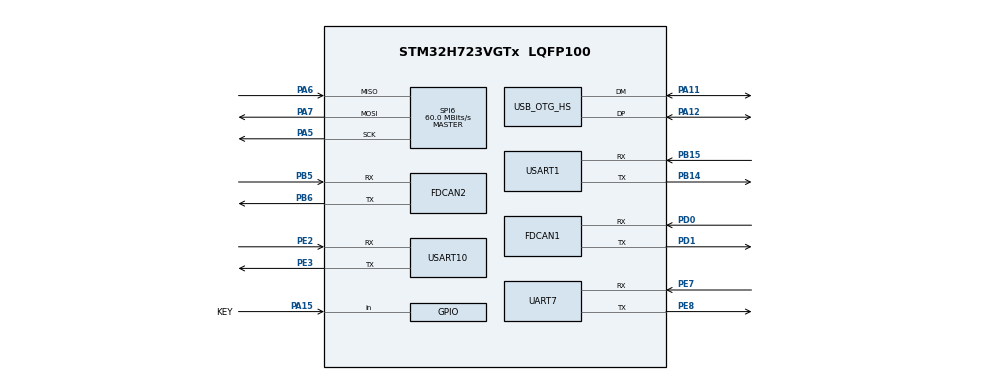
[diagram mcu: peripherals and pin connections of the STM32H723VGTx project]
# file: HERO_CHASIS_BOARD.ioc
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CORTEX_M7.default_mode_Activation=1
Dma.Request0=USART10_RX
Dma.Request1=USART10_TX
Dma.Request2=USART1_RX
Dma.Request3=UART7_RX
Dma.Request4=UART7_TX
Dma.UART7_RX.3.Direction=DMA_PERIPH_TO_MEMORY
Dma.UART7_RX.3.EventEnable=DISABLE
Dma.UART7_RX.3.FIFOMode=DMA_FIFOMODE_DISABLE
Dma.UART7_RX.3.Instance=DMA1_Stream3
Dma.UART7_RX.3.MemDataAlignment=DMA_MDATAALIGN_BYTE
Dma.UART7_RX.3.MemInc=DMA_MINC_ENABLE
Dma.UART7_RX.3.Mode=DMA_CIRCULAR
Dma.UART7_RX.3.PeriphDataAlignment=DMA_PDATAALIGN_BYTE
Dma.UART7_RX.3.PeriphInc=DMA_PINC_DISABLE
Dma.UART7_RX.3.Polarity=HAL_DMAMUX_REQ_GEN_RISING
Dma.UART7_RX.3.Priority=DMA_PRIORITY_HIGH
Dma.UART7_RX.3.RequestNumber=1
Dma.UART7_RX.3.SignalID=NONE
Dma.UART7_RX.3.SyncEnable=DISABLE
Dma.UART7_RX.3.SyncPolarity=HAL_DMAMUX_SYNC_NO_EVENT
Dma.UART7_RX.3.SyncRequestNumber=1
Dma.UART7_RX.3.SyncSignalID=NONE
Dma.UART7_TX.4.Direction=DMA_MEMORY_TO_PERIPH
Dma.UART7_TX.4.EventEnable=DISABLE
Dma.UART7_TX.4.FIFOMode=DMA_FIFOMODE_DISABLE
Dma.UART7_TX.4.Instance=DMA1_Stream4
Dma.UART7_TX.4.MemDataAlignment=DMA_MDATAALIGN_BYTE
Dma.UART7_TX.4.MemInc=DMA_MINC_ENABLE
Dma.UART7_TX.4.Mode=DMA_NORMAL
Dma.UART7_TX.4.PeriphDataAlignment=DMA_PDATAALIGN_BYTE
Dma.UART7_TX.4.PeriphInc=DMA_PINC_DISABLE
Dma.UART7_TX.4.Polarity=HAL_DMAMUX_REQ_GEN_RISING
Dma.UART7_TX.4.Priority=DMA_PRIORITY_MEDIUM
Dma.UART7_TX.4.RequestNumber=1
Dma.UART7_TX.4.SignalID=NONE
Dma.UART7_TX.4.SyncEnable=DISABLE
Dma.UART7_TX.4.SyncPolarity=HAL_DMAMUX_SYNC_NO_EVENT
Dma.UART7_TX.4.SyncRequestNumber=1
Dma.UART7_TX.4.SyncSignalID=NONE
Dma.USART10_RX.0.Direction=DMA_PERIPH_TO_MEMORY
Dma.USART10_RX.0.EventEnable=DISABLE
Dma.USART10_RX.0.FIFOMode=DMA_FIFOMODE_DISABLE
Dma.USART10_RX.0.Instance=DMA1_Stream0
Dma.USART10_RX.0.MemDataAlignment=DMA_MDATAALIGN_BYTE
Dma.USART10_RX.0.MemInc=DMA_MINC_ENABLE
Dma.USART10_RX.0.Mode=DMA_CIRCULAR
Dma.USART10_RX.0.PeriphDataAlignment=DMA_PDATAALIGN_BYTE
Dma.USART10_RX.0.PeriphInc=DMA_PINC_DISABLE
Dma.USART10_RX.0.Polarity=HAL_DMAMUX_REQ_GEN_RISING
Dma.USART10_RX.0.Priority=DMA_PRIORITY_LOW
Dma.USART10_RX.0.RequestNumber=1
Dma.USART10_RX.0.SignalID=NONE
Dma.USART10_RX.0.SyncEnable=DISABLE
Dma.USART10_RX.0.SyncPolarity=HAL_DMAMUX_SYNC_NO_EVENT
Dma.USART10_RX.0.SyncRequestNumber=1
Dma.USART10_RX.0.SyncSignalID=NONE
Dma.USART10_TX.1.Direction=DMA_MEMORY_TO_PERIPH
Dma.USART10_TX.1.EventEnable=DISABLE
Dma.USART10_TX.1.FIFOMode=DMA_FIFOMODE_DISABLE
Dma.USART10_TX.1.Instance=DMA1_Stream1
Dma.USART10_TX.1.MemDataAlignment=DMA_MDATAALIGN_BYTE
Dma.USART10_TX.1.MemInc=DMA_MINC_ENABLE
Dma.USART10_TX.1.Mode=DMA_NORMAL
Dma.USART10_TX.1.PeriphDataAlignment=DMA_PDATAALIGN_BYTE
Dma.USART10_TX.1.PeriphInc=DMA_PINC_DISABLE
Dma.USART10_TX.1.Polarity=HAL_DMAMUX_REQ_GEN_RISING
Dma.USART10_TX.1.Priority=DMA_PRIORITY_LOW
Dma.USART10_TX.1.RequestNumber=1
Dma.USART10_TX.1.SignalID=NONE
Dma.USART10_TX.1.SyncEnable=DISABLE
Dma.USART10_TX.1.SyncPolarity=HAL_DMAMUX_SYNC_NO_EVENT
Dma.USART10_TX.1.SyncRequestNumber=1
Dma.USART10_TX.1.SyncSignalID=NONE
Dma.USART1_RX.2.Direction=DMA_PERIPH_TO_MEMORY
Dma.USART1_RX.2.EventEnable=DISABLE
Dma.USART1_RX.2.FIFOMode=DMA_FIFOMODE_DISABLE
Dma.USART1_RX.2.Instance=DMA1_Stream2
Dma.USART1_RX.2.MemDataAlignment=DMA_MDATAALIGN_BYTE
Dma.USART1_RX.2.MemInc=DMA_MINC_ENABLE
Dma.USART1_RX.2.Mode=DMA_CIRCULAR
Dma.USART1_RX.2.PeriphDataAlignment=DMA_PDATAALIGN_BYTE
Dma.USART1_RX.2.PeriphInc=DMA_PINC_DISABLE
Dma.USART1_RX.2.Polarity=HAL_DMAMUX_REQ_GEN_RISING
Dma.USART1_RX.2.Priority=DMA_PRIORITY_HIGH
Dma.USART1_RX.2.RequestNumber=1
Dma.USART1_RX.2.SignalID=NONE
Dma.USART1_RX.2.SyncEnable=DISABLE
Dma.USART1_RX.2.SyncPolarity=HAL_DMAMUX_SYNC_NO_EVENT
Dma.USART1_RX.2.SyncRequestNumber=1
Dma.USART1_RX.2.SyncSignalID=NONE
FDCAN1.CalculateBaudRateNominal=1000000
FDCAN1.CalculateTimeBitNominal=1000
FDCAN1.CalculateTimeQuantumNominal=25.0
FDCAN1.DataPrescaler=3
FDCAN1.DataSyncJumpWidth=10
FDCAN1.DataTimeSeg1=29
FDCAN1.DataTimeSeg2=10
FDCAN1.NominalPrescaler=3
FDCAN1.NominalSyncJumpWidth=10
FDCAN1.NominalTimeSeg1=29
FDCAN1.NominalTimeSeg2=10
FDCAN1.ProtocolException=ENABLE
FDCAN1.RxFifo0ElmtsNbr=3
FDCAN1.StdFiltersNbr=1
FDCAN1.TxFifoQueueElmtsNbr=3
FDCAN2.CalculateBaudRateNominal=1000000
FDCAN2.CalculateTimeBitNominal=1000
FDCAN2.CalculateTimeQuantumNominal=25.0
FDCAN2.DataPrescaler=3
FDCAN2.DataSyncJumpWidth=10
FDCAN2.DataTimeSeg1=29
FDCAN2.DataTimeSeg2=10
FDCAN2.NominalPrescaler=3
FDCAN2.NominalSyncJumpWidth=10
FDCAN2.NominalTimeSeg1=29
FDCAN2.NominalTimeSeg2=10
FDCAN2.ProtocolException=ENABLE
FDCAN2.RxFifo0ElmtsNbr=3
FDCAN2.StdFiltersNbr=1
FDCAN2.TxFifoQueueElmtsNbr=3
FREERTOS.Tasks01=defaultTask,24,128,StartDefaultTask,Default,NULL,Dynamic,NULL,NULL
Mcu.Family=STM32H7
Mcu.Name=STM32H723VGTx
Mcu.Package=LQFP100
NVIC.DMA1_Stream0_IRQn=true\:5\:0\:false\:false\:true\:true\:false\:true\:true
NVIC.DMA1_Stream1_IRQn=true\:5\:0\:false\:false\:true\:true\:false\:true\:true
NVIC.DMA1_Stream2_IRQn=true\:5\:0\:false\:false\:true\:true\:false\:true\:true
NVIC.DMA1_Stream3_IRQn=true\:5\:0\:false\:false\:true\:true\:false\:true\:true
NVIC.DMA1_Stream4_IRQn=true\:5\:0\:false\:false\:true\:true\:false\:true\:true
NVIC.OTG_HS_IRQn=true\:5\:0\:false\:false\:true\:true\:false\:true\:true
NVIC.PriorityGroup=NVIC_PRIORITYGROUP_4
NVIC.TIM8_UP_TIM13_IRQn=true\:15\:0\:false\:false\:true\:false\:false\:true\:true
NVIC.TimeBase=TIM8_UP_TIM13_IRQn
NVIC.TimeBaseIP=TIM8
NVIC.UART7_IRQn=true\:5\:0\:false\:false\:true\:true\:true\:true\:true
NVIC.USART10_IRQn=true\:5\:0\:false\:false\:true\:true\:true\:true\:true
NVIC.USART1_IRQn=true\:5\:0\:false\:false\:true\:true\:true\:true\:true
PA11.Mode=Device_Only_FS
PA11.Signal=USB_OTG_HS_DM
PA12.Mode=Device_Only_FS
PA12.Signal=USB_OTG_HS_DP
PA13(JTMS/SWDIO).Mode=Serial_Wire
PA13(JTMS/SWDIO).Signal=DEBUG_JTMS-SWDIO
PA14(JTCK/SWCLK).Mode=Serial_Wire
PA14(JTCK/SWCLK).Signal=DEBUG_JTCK-SWCLK
PA15(JTDI).GPIO_Label=KEY
PA15(JTDI).GPIO_PuPd=GPIO_PULLUP
PA15(JTDI).Signal=GPIO_Input
PA5.Mode=Full_Duplex_Master
PA5.Signal=SPI6_SCK
PA6.Mode=Full_Duplex_Master
PA6.Signal=SPI6_MISO
PA7.Mode=Full_Duplex_Master
PA7.Signal=SPI6_MOSI
PB14.Mode=Asynchronous
PB14.Signal=USART1_TX
PB15.Mode=Asynchronous
PB15.Signal=USART1_RX
PB5.Mode=FDCAN_Activate
PB5.Signal=FDCAN2_RX
PB6.Mode=FDCAN_Activate
PB6.Signal=FDCAN2_TX
PD0.Mode=FDCAN_Activate
PD0.Signal=FDCAN1_RX
PD1.Mode=FDCAN_Activate
PD1.Signal=FDCAN1_TX
PE2.Mode=Asynchronous
PE2.Signal=USART10_RX
PE3.Mode=Asynchronous
PE3.Signal=USART10_TX
PE7.Mode=Asynchronous
PE7.Signal=UART7_RX
PE8.Mode=Asynchronous
PE8.Signal=UART7_TX
PH0-OSC_IN.Mode=HSE-External-Oscillator
PH0-OSC_IN.Signal=RCC_OSC_IN
PH1-OSC_OUT.Mode=HSE-External-Oscillator
PH1-OSC_OUT.Signal=RCC_OSC_OUT
ProjectManager.HeapSize=0x200
ProjectManager.StackSize=0x400
ProjectManager.TargetToolchain=MDK-ARM V5.32
RCC.ADCFreq_Value=120000000
RCC.APB1Freq_Value=120000000
RCC.APB2Freq_Value=120000000
RCC.APB3Freq_Value=120000000
RCC.APB4Freq_Value=120000000
RCC.CortexFreq_Value=480000000
RCC.D1PPRE=RCC_APB3_DIV2
RCC.D2PPRE1=RCC_APB1_DIV2
RCC.D2PPRE2=RCC_APB2_DIV2
RCC.D3PPRE=RCC_APB4_DIV2
RCC.DIVM1=2
RCC.DIVM2=2
RCC.DIVN1=40
RCC.DIVN2=20
RCC.DIVP1=1
RCC.FDCANCLockSelection=RCC_FDCANCLKSOURCE_PLL2
RCC.HCLKFreq_Value=240000000
RCC.HPRE=RCC_HCLK_DIV2
RCC.HSE_VALUE=24000000
RCC.PLL2FRACN=0
RCC.PLLFRACN=0
RCC.PLLSourceVirtual=RCC_PLLSOURCE_HSE
RCC.SYSCLKFreq_VALUE=480000000
RCC.SYSCLKSource=RCC_SYSCLKSOURCE_PLLCLK
RCC.USBCLockSelection=RCC_USBCLKSOURCE_HSI48
RCC.USBFreq_Value=48000000
SPI6.CalculateBaudRate=60.0 MBits/s
SPI6.Direction=SPI_DIRECTION_2LINES
SPI6.Mode=SPI_MODE_MASTER
SPI6.VirtualType=VM_MASTER
USART1.VirtualMode-Asynchronous=VM_ASYNC
USART10.VirtualMode=VM_ASYNC
USB_DEVICE.CLASS_NAME_HS=CDC
USB_DEVICE.VirtualMode=Cdc
USB_DEVICE.VirtualModeHS=Cdc_HS
USB_OTG_HS.VirtualMode-Device_Only_FS=Device_Only_FS
VP_FREERTOS_VS_CMSIS_V2.Mode=CMSIS_V2
VP_MEMORYMAP_VS_MEMORYMAP.Mode=CurAppReg
VP_SYS_VS_tim8.Mode=TIM8
VP_USB_DEVICE_VS_USB_DEVICE_CDC_HS.Mode=CDC_HS
board=custom

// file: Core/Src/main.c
/* USER CODE BEGIN Header */
/**
  ******************************************************************************
  * @file           : main.c
  * @brief          : Main program body
  ******************************************************************************
  * @attention
  *
  * Copyright (c) 2025 STMicroelectronics.
  * All rights reserved.
  *
  * This software is licensed under terms that can be found in the LICENSE file
  * in the root directory of this software component.
  * If no LICENSE file comes with this software, it is provided AS-IS.
  *
  ******************************************************************************
  */
/* USER CODE END Header */
#include "main.h"
#include "cmsis_os.h"
#include "dma.h"
#include "fdcan.h"
#include "spi.h"
#include "usart.h"
#include "usb_device.h"
#include "gpio.h"

/* USER CODE BEGIN Includes */
#include "usbd_cdc_if.h"

/* USER CODE END Includes */

void SystemClock_Config(void);
void PeriphCommonClock_Config(void);
static void MPU_Config(void);
void MX_FREERTOS_Init(void);

int main(void)
{

  /* MPU Configuration--------------------------------------------------------*/
  MPU_Config();

  /* MCU Configuration--------------------------------------------------------*/

  /* Reset of all peripherals, Initializes the Flash interface and the Systick. */
  HAL_Init();

  /* Configure the system clock */
  SystemClock_Config();

  /* Configure the peripherals common clocks */
  PeriphCommonClock_Config();

  /* Initialize all configured peripherals */
  MX_GPIO_Init();
  MX_DMA_Init();
  MX_FDCAN1_Init();
  MX_FDCAN2_Init();
  MX_SPI6_Init();
  MX_USART10_UART_Init();
  MX_USART1_UART_Init();
  MX_UART7_Init();

  /* Init scheduler */
  osKernelInitialize();  /* Call init function for freertos objects (in cmsis_os2.c) */
  MX_FREERTOS_Init();

  /* Start scheduler */
  osKernelStart();

  /* We should never get here as control is now taken by the scheduler */

  /* Infinite loop */
  /* USER CODE BEGIN WHILE */
  while (1)
  {
    usb_printf("Hello World!\r\n");

    /* USER CODE END WHILE */

  }
}

void SystemClock_Config(void)
{
  RCC_OscInitTypeDef RCC_OscInitStruct = {0};
  RCC_ClkInitTypeDef RCC_ClkInitStruct = {0};

  /** Supply configuration update enable
  */
  HAL_PWREx_ConfigSupply(PWR_LDO_SUPPLY);

  /** Configure the main internal regulator output voltage
  */
  __HAL_PWR_VOLTAGESCALING_CONFIG(PWR_REGULATOR_VOLTAGE_SCALE0);

  while(!__HAL_PWR_GET_FLAG(PWR_FLAG_VOSRDY)) {}

  /** Initializes the RCC Oscillators according to the specified parameters
  * in the RCC_OscInitTypeDef structure.
  */
  RCC_OscInitStruct.OscillatorType = RCC_OSCILLATORTYPE_HSI48|RCC_OSCILLATORTYPE_HSE;
  RCC_OscInitStruct.HSEState = RCC_HSE_ON;
  RCC_OscInitStruct.HSI48State = RCC_HSI48_ON;
  RCC_OscInitStruct.PLL.PLLState = RCC_PLL_ON;
  RCC_OscInitStruct.PLL.PLLSource = RCC_PLLSOURCE_HSE;
  RCC_OscInitStruct.PLL.PLLM = 2;
  RCC_OscInitStruct.PLL.PLLN = 40;
  RCC_OscInitStruct.PLL.PLLP = 1;
  RCC_OscInitStruct.PLL.PLLQ = 2;
  RCC_OscInitStruct.PLL.PLLR = 2;
  RCC_OscInitStruct.PLL.PLLRGE = RCC_PLL1VCIRANGE_3;
  RCC_OscInitStruct.PLL.PLLVCOSEL = RCC_PLL1VCOWIDE;
  RCC_OscInitStruct.PLL.PLLFRACN = 0;
  if (HAL_RCC_OscConfig(&RCC_OscInitStruct) != HAL_OK)
  {
    Error_Handler();
  }

  /** Initializes the CPU, AHB and APB buses clocks
  */
  RCC_ClkInitStruct.ClockType = RCC_CLOCKTYPE_HCLK|RCC_CLOCKTYPE_SYSCLK
                              |RCC_CLOCKTYPE_PCLK1|RCC_CLOCKTYPE_PCLK2
                              |RCC_CLOCKTYPE_D3PCLK1|RCC_CLOCKTYPE_D1PCLK1;
  RCC_ClkInitStruct.SYSCLKSource = RCC_SYSCLKSOURCE_PLLCLK;
  RCC_ClkInitStruct.SYSCLKDivider = RCC_SYSCLK_DIV1;
  RCC_ClkInitStruct.AHBCLKDivider = RCC_HCLK_DIV2;
  RCC_ClkInitStruct.APB3CLKDivider = RCC_APB3_DIV2;
  RCC_ClkInitStruct.APB1CLKDivider = RCC_APB1_DIV2;
  RCC_ClkInitStruct.APB2CLKDivider = RCC_APB2_DIV2;
  RCC_ClkInitStruct.APB4CLKDivider = RCC_APB4_DIV2;

  if (HAL_RCC_ClockConfig(&RCC_ClkInitStruct, FLASH_LATENCY_3) != HAL_OK)
  {
    Error_Handler();
  }
}

void PeriphCommonClock_Config(void)
{
  RCC_PeriphCLKInitTypeDef PeriphClkInitStruct = {0};

  /** Initializes the peripherals clock
  */
  PeriphClkInitStruct.PeriphClockSelection = RCC_PERIPHCLK_FDCAN;
  PeriphClkInitStruct.PLL2.PLL2M = 2;
  PeriphClkInitStruct.PLL2.PLL2N = 20;
  PeriphClkInitStruct.PLL2.PLL2P = 2;
  PeriphClkInitStruct.PLL2.PLL2Q = 2;
  PeriphClkInitStruct.PLL2.PLL2R = 2;
  PeriphClkInitStruct.PLL2.PLL2RGE = RCC_PLL2VCIRANGE_3;
  PeriphClkInitStruct.PLL2.PLL2VCOSEL = RCC_PLL2VCOWIDE;
  PeriphClkInitStruct.PLL2.PLL2FRACN = 0;
  PeriphClkInitStruct.FdcanClockSelection = RCC_FDCANCLKSOURCE_PLL2;
  if (HAL_RCCEx_PeriphCLKConfig(&PeriphClkInitStruct) != HAL_OK)
  {
    Error_Handler();
  }
}

 /* MPU Configuration */

void MPU_Config(void)
{
  MPU_Region_InitTypeDef MPU_InitStruct = {0};

  /* Disables the MPU */
  HAL_MPU_Disable();

  /** Initializes and configures the Region and the memory to be protected
  */
  MPU_InitStruct.Enable = MPU_REGION_ENABLE;
  MPU_InitStruct.Number = MPU_REGION_NUMBER0;
  MPU_InitStruct.BaseAddress = 0x0;
  MPU_InitStruct.Size = MPU_REGION_SIZE_4GB;
  MPU_InitStruct.SubRegionDisable = 0x87;
  MPU_InitStruct.TypeExtField = MPU_TEX_LEVEL0;
  MPU_InitStruct.AccessPermission = MPU_REGION_NO_ACCESS;
  MPU_InitStruct.DisableExec = MPU_INSTRUCTION_ACCESS_DISABLE;
  MPU_InitStruct.IsShareable = MPU_ACCESS_SHAREABLE;
  MPU_InitStruct.IsCacheable = MPU_ACCESS_NOT_CACHEABLE;
  MPU_InitStruct.IsBufferable = MPU_ACCESS_NOT_BUFFERABLE;

  HAL_MPU_ConfigRegion(&MPU_InitStruct);
  /* Enables the MPU */
  HAL_MPU_Enable(MPU_PRIVILEGED_DEFAULT);

}

void HAL_TIM_PeriodElapsedCallback(TIM_HandleTypeDef *htim)
{
  if (htim->Instance == TIM8)
  {
    HAL_IncTick();
  }
}

void Error_Handler(void)
{
  __disable_irq();
  while (1)
  {
  }
}

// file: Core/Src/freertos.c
/* USER CODE BEGIN Header */
/**
  ******************************************************************************
  * File Name          : freertos.c
  * Description        : Code for freertos applications
  ******************************************************************************
  * @attention
  *
  * Copyright (c) 2025 STMicroelectronics.
  * All rights reserved.
  *
  * This software is licensed under terms that can be found in the LICENSE file
  * in the root directory of this software component.
  * If no LICENSE file comes with this software, it is provided AS-IS.
  *
  ******************************************************************************
  */
/* USER CODE END Header */

#include "FreeRTOS.h"
#include "task.h"
#include "main.h"
#include "cmsis_os.h"

/* Definitions for defaultTask */
osThreadId_t defaultTaskHandle;
const osThreadAttr_t defaultTask_attributes = {
  .name = "defaultTask",
  .stack_size = 128 * 4,
  .priority = (osPriority_t) osPriorityNormal,
};

/* USER CODE BEGIN FunctionPrototypes */
void start_task(void const *argument);
/* USER CODE END FunctionPrototypes */

void StartDefaultTask(void *argument);

extern void MX_USB_DEVICE_Init(void);
void MX_FREERTOS_Init(void); /* (MISRA C 2004 rule 8.1) */

void MX_FREERTOS_Init(void) {

  /* Create the thread(s) */
  /* creation of defaultTask */
  defaultTaskHandle = osThreadNew(StartDefaultTask, NULL, &defaultTask_attributes);

}

void StartDefaultTask(void *argument)
{
  /* init code for USB_DEVICE */
  MX_USB_DEVICE_Init();
  for(;;)
  {
    osDelay(1);
  }
}

/* USER CODE BEGIN Application */
__weak void start_task(void const *argument)
{
  /* USER CODE BEGIN test_task */
  System_Resource_Init();
  /* Infinite loop */
  for (;;)
  {
    Task_start();
    /* Delete_Graph the default task. */
    osThreadTerminate(startTaskHandle);
  }
  /* USER CODE END test_task */
}

/* USER CODE END Application */
